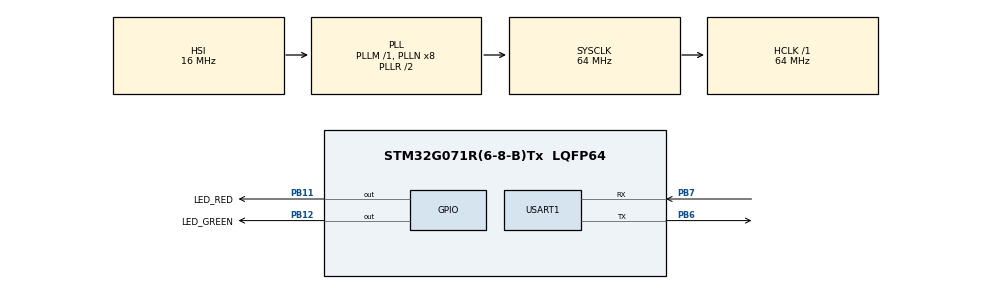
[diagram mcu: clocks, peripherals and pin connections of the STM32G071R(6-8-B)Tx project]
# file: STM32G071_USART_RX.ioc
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Dma.Request0=USART1_RX
Dma.Request1=USART1_TX
Dma.USART1_RX.0.Direction=DMA_PERIPH_TO_MEMORY
Dma.USART1_RX.0.EventEnable=DISABLE
Dma.USART1_RX.0.Instance=DMA1_Channel1
Dma.USART1_RX.0.MemDataAlignment=DMA_MDATAALIGN_BYTE
Dma.USART1_RX.0.MemInc=DMA_MINC_ENABLE
Dma.USART1_RX.0.Mode=DMA_NORMAL
Dma.USART1_RX.0.PeriphDataAlignment=DMA_PDATAALIGN_BYTE
Dma.USART1_RX.0.PeriphInc=DMA_PINC_DISABLE
Dma.USART1_RX.0.Polarity=HAL_DMAMUX_REQ_GEN_RISING
Dma.USART1_RX.0.Priority=DMA_PRIORITY_LOW
Dma.USART1_RX.0.RequestNumber=1
Dma.USART1_RX.0.SignalID=NONE
Dma.USART1_RX.0.SyncEnable=DISABLE
Dma.USART1_RX.0.SyncPolarity=HAL_DMAMUX_SYNC_NO_EVENT
Dma.USART1_RX.0.SyncRequestNumber=1
Dma.USART1_RX.0.SyncSignalID=NONE
Dma.USART1_TX.1.Direction=DMA_MEMORY_TO_PERIPH
Dma.USART1_TX.1.EventEnable=DISABLE
Dma.USART1_TX.1.Instance=DMA1_Channel2
Dma.USART1_TX.1.MemDataAlignment=DMA_MDATAALIGN_BYTE
Dma.USART1_TX.1.MemInc=DMA_MINC_ENABLE
Dma.USART1_TX.1.Mode=DMA_NORMAL
Dma.USART1_TX.1.PeriphDataAlignment=DMA_PDATAALIGN_BYTE
Dma.USART1_TX.1.PeriphInc=DMA_PINC_DISABLE
Dma.USART1_TX.1.Polarity=HAL_DMAMUX_REQ_GEN_RISING
Dma.USART1_TX.1.Priority=DMA_PRIORITY_LOW
Dma.USART1_TX.1.RequestNumber=1
Dma.USART1_TX.1.SignalID=NONE
Dma.USART1_TX.1.SyncEnable=DISABLE
Dma.USART1_TX.1.SyncPolarity=HAL_DMAMUX_SYNC_NO_EVENT
Dma.USART1_TX.1.SyncRequestNumber=1
Dma.USART1_TX.1.SyncSignalID=NONE
Mcu.Family=STM32G0
Mcu.Name=STM32G071R(6-8-B)Tx
Mcu.Package=LQFP64
NVIC.DMA1_Channel1_IRQn=true\:0\:0\:false\:false\:true\:false\:true\:true
NVIC.DMA1_Channel2_3_IRQn=true\:0\:0\:false\:false\:true\:false\:true\:true
NVIC.USART1_IRQn=true\:0\:0\:false\:false\:true\:true\:true\:true
PA13.Mode=Serial_Wire
PA13.Signal=SYS_SWDIO
PA14-BOOT0.Mode=Serial_Wire
PA14-BOOT0.Signal=SYS_SWCLK
PB11.GPIO_Label=LED_RED
PB11.Signal=GPIO_Output
PB12.GPIO_Label=LED_GREEN
PB12.Signal=GPIO_Output
PB6.Mode=Asynchronous
PB6.Signal=USART1_TX
PB7.Mode=Asynchronous
PB7.Signal=USART1_RX
ProjectManager.HeapSize=0x200
ProjectManager.StackSize=0x400
ProjectManager.TargetToolchain=STM32CubeIDE
RCC.ADCFreq_Value=64000000
RCC.AHBFreq_Value=64000000
RCC.CortexFreq_Value=64000000
RCC.EXTERNAL_CLOCK_VALUE=48000
RCC.HCLKFreq_Value=64000000
RCC.HSE_VALUE=8000000
RCC.HSI_VALUE=16000000
RCC.LSE_VALUE=32768
RCC.SYSCLKFreq_VALUE=64000000
RCC.SYSCLKSource=RCC_SYSCLKSOURCE_PLLCLK
RCC.VCOOutputFreq_Value=128000000
USART1.VirtualMode-Asynchronous=VM_ASYNC
board=custom

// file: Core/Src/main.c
/* USER CODE BEGIN Header */
/**
  ******************************************************************************
  * @file           : main.c
  * @brief          : Main program body
  ******************************************************************************
  * @attention
  *
  * Copyright (c) 2024 STMicroelectronics.
  * All rights reserved.
  *
  * This software is licensed under terms that can be found in the LICENSE file
  * in the root directory of this software component.
  * If no LICENSE file comes with this software, it is provided AS-IS.
  *
  ******************************************************************************
  */
/* USER CODE END Header */
#include "main.h"

/* USER CODE BEGIN Includes */
#include <stdbool.h>

/* USER CODE END Includes */

UART_HandleTypeDef huart1;
DMA_HandleTypeDef hdma_usart1_rx;
DMA_HandleTypeDef hdma_usart1_tx;

void SystemClock_Config(void);
static void MX_GPIO_Init(void);
static void MX_DMA_Init(void);
static void MX_USART1_UART_Init(void);

/* USER CODE BEGIN 0 */

uint8_t Rx_Data[10];

/* USER CODE END 0 */

int main(void)
{

  /* MCU Configuration--------------------------------------------------------*/

  /* Reset of all peripherals, Initializes the Flash interface and the Systick. */
  HAL_Init();

  /* Configure the system clock */
  SystemClock_Config();

  /* Initialize all configured peripherals */
  MX_GPIO_Init();
  MX_DMA_Init();
  MX_USART1_UART_Init();
  /* USER CODE BEGIN 2 */

  /*SysTick Configuration */
  SystemCoreClockUpdate();

  /* Generate interrupt for each 1 ms*/
  SysTick_Config(SystemCoreClock/1);
//  SysTick->CTRL = 0;
//  SysTick->VAL  = 0;
//  SysTick->CTRL = (SysTick_CTRL_TICKINT_Msk
//		  	  	   |SysTick_CTRL_ENABLE_Msk
//				   |SysTick_CTRL_CLKSOURCE_Msk);

  /* USER CODE END 2 */

  /* Infinite loop */
  /* USER CODE BEGIN WHILE */
  while (true)
  {
    /* USER CODE END WHILE */

    /* USER CODE BEGIN 3 */
	  HAL_UART_Receive(&huart1, Rx_Data, sizeof(Rx_Data), 10000);
	  HAL_GPIO_TogglePin(LED_GREEN_GPIO_Port, LED_GREEN_Pin);
	  HAL_Delay(250);
  }
  /* USER CODE END 3 */
}

void SystemClock_Config(void)
{
  RCC_OscInitTypeDef RCC_OscInitStruct = {0};
  RCC_ClkInitTypeDef RCC_ClkInitStruct = {0};

  /** Configure the main internal regulator output voltage
  */
  HAL_PWREx_ControlVoltageScaling(PWR_REGULATOR_VOLTAGE_SCALE1);

  /** Initializes the RCC Oscillators according to the specified parameters
  * in the RCC_OscInitTypeDef structure.
  */
  RCC_OscInitStruct.OscillatorType = RCC_OSCILLATORTYPE_HSI;
  RCC_OscInitStruct.HSIState = RCC_HSI_ON;
  RCC_OscInitStruct.HSIDiv = RCC_HSI_DIV1;
  RCC_OscInitStruct.HSICalibrationValue = RCC_HSICALIBRATION_DEFAULT;
  RCC_OscInitStruct.PLL.PLLState = RCC_PLL_ON;
  RCC_OscInitStruct.PLL.PLLSource = RCC_PLLSOURCE_HSI;
  RCC_OscInitStruct.PLL.PLLM = RCC_PLLM_DIV1;
  RCC_OscInitStruct.PLL.PLLN = 8;
  RCC_OscInitStruct.PLL.PLLP = RCC_PLLP_DIV2;
  RCC_OscInitStruct.PLL.PLLQ = RCC_PLLQ_DIV2;
  RCC_OscInitStruct.PLL.PLLR = RCC_PLLR_DIV2;
  if (HAL_RCC_OscConfig(&RCC_OscInitStruct) != HAL_OK)
  {
    Error_Handler();
  }

  /** Initializes the CPU, AHB and APB buses clocks
  */
  RCC_ClkInitStruct.ClockType = RCC_CLOCKTYPE_HCLK|RCC_CLOCKTYPE_SYSCLK
                              |RCC_CLOCKTYPE_PCLK1;
  RCC_ClkInitStruct.SYSCLKSource = RCC_SYSCLKSOURCE_PLLCLK;
  RCC_ClkInitStruct.AHBCLKDivider = RCC_SYSCLK_DIV1;
  RCC_ClkInitStruct.APB1CLKDivider = RCC_HCLK_DIV1;

  if (HAL_RCC_ClockConfig(&RCC_ClkInitStruct, FLASH_LATENCY_2) != HAL_OK)
  {
    Error_Handler();
  }
}

static void MX_USART1_UART_Init(void)
{

  huart1.Instance = USART1;
  huart1.Init.BaudRate = 115200;
  huart1.Init.WordLength = UART_WORDLENGTH_8B;
  huart1.Init.StopBits = UART_STOPBITS_1;
  huart1.Init.Parity = UART_PARITY_NONE;
  huart1.Init.Mode = UART_MODE_TX_RX;
  huart1.Init.HwFlowCtl = UART_HWCONTROL_NONE;
  huart1.Init.OverSampling = UART_OVERSAMPLING_16;
  huart1.Init.OneBitSampling = UART_ONE_BIT_SAMPLE_DISABLE;
  huart1.Init.ClockPrescaler = UART_PRESCALER_DIV1;
  huart1.AdvancedInit.AdvFeatureInit = UART_ADVFEATURE_NO_INIT;
  if (HAL_UART_Init(&huart1) != HAL_OK)
  {
    Error_Handler();
  }
  if (HAL_UARTEx_SetTxFifoThreshold(&huart1, UART_TXFIFO_THRESHOLD_1_8) != HAL_OK)
  {
    Error_Handler();
  }
  if (HAL_UARTEx_SetRxFifoThreshold(&huart1, UART_RXFIFO_THRESHOLD_1_8) != HAL_OK)
  {
    Error_Handler();
  }
  if (HAL_UARTEx_DisableFifoMode(&huart1) != HAL_OK)
  {
    Error_Handler();
  }

}

static void MX_DMA_Init(void)
{

  /* DMA controller clock enable */
  __HAL_RCC_DMA1_CLK_ENABLE();

  /* DMA interrupt init */
  /* DMA1_Channel1_IRQn interrupt configuration */
  HAL_NVIC_SetPriority(DMA1_Channel1_IRQn, 0, 0);
  HAL_NVIC_EnableIRQ(DMA1_Channel1_IRQn);
  /* DMA1_Channel2_3_IRQn interrupt configuration */
  HAL_NVIC_SetPriority(DMA1_Channel2_3_IRQn, 0, 0);
  HAL_NVIC_EnableIRQ(DMA1_Channel2_3_IRQn);

}

static void MX_GPIO_Init(void)
{
  GPIO_InitTypeDef GPIO_InitStruct = {0};

  /* GPIO Ports Clock Enable */
  __HAL_RCC_GPIOB_CLK_ENABLE();
  __HAL_RCC_GPIOA_CLK_ENABLE();

  /*Configure GPIO pin Output Level */
  HAL_GPIO_WritePin(GPIOB, LED_RED_Pin|LED_GREEN_Pin, GPIO_PIN_RESET);

  /*Configure GPIO pins : LED_RED_Pin LED_GREEN_Pin */
  GPIO_InitStruct.Pin = LED_RED_Pin|LED_GREEN_Pin;
  GPIO_InitStruct.Mode = GPIO_MODE_OUTPUT_PP;
  GPIO_InitStruct.Pull = GPIO_NOPULL;
  GPIO_InitStruct.Speed = GPIO_SPEED_FREQ_LOW;
  HAL_GPIO_Init(GPIOB, &GPIO_InitStruct);

}

void Error_Handler(void)
{
  __disable_irq();
  while (1)
  {
  }
}
